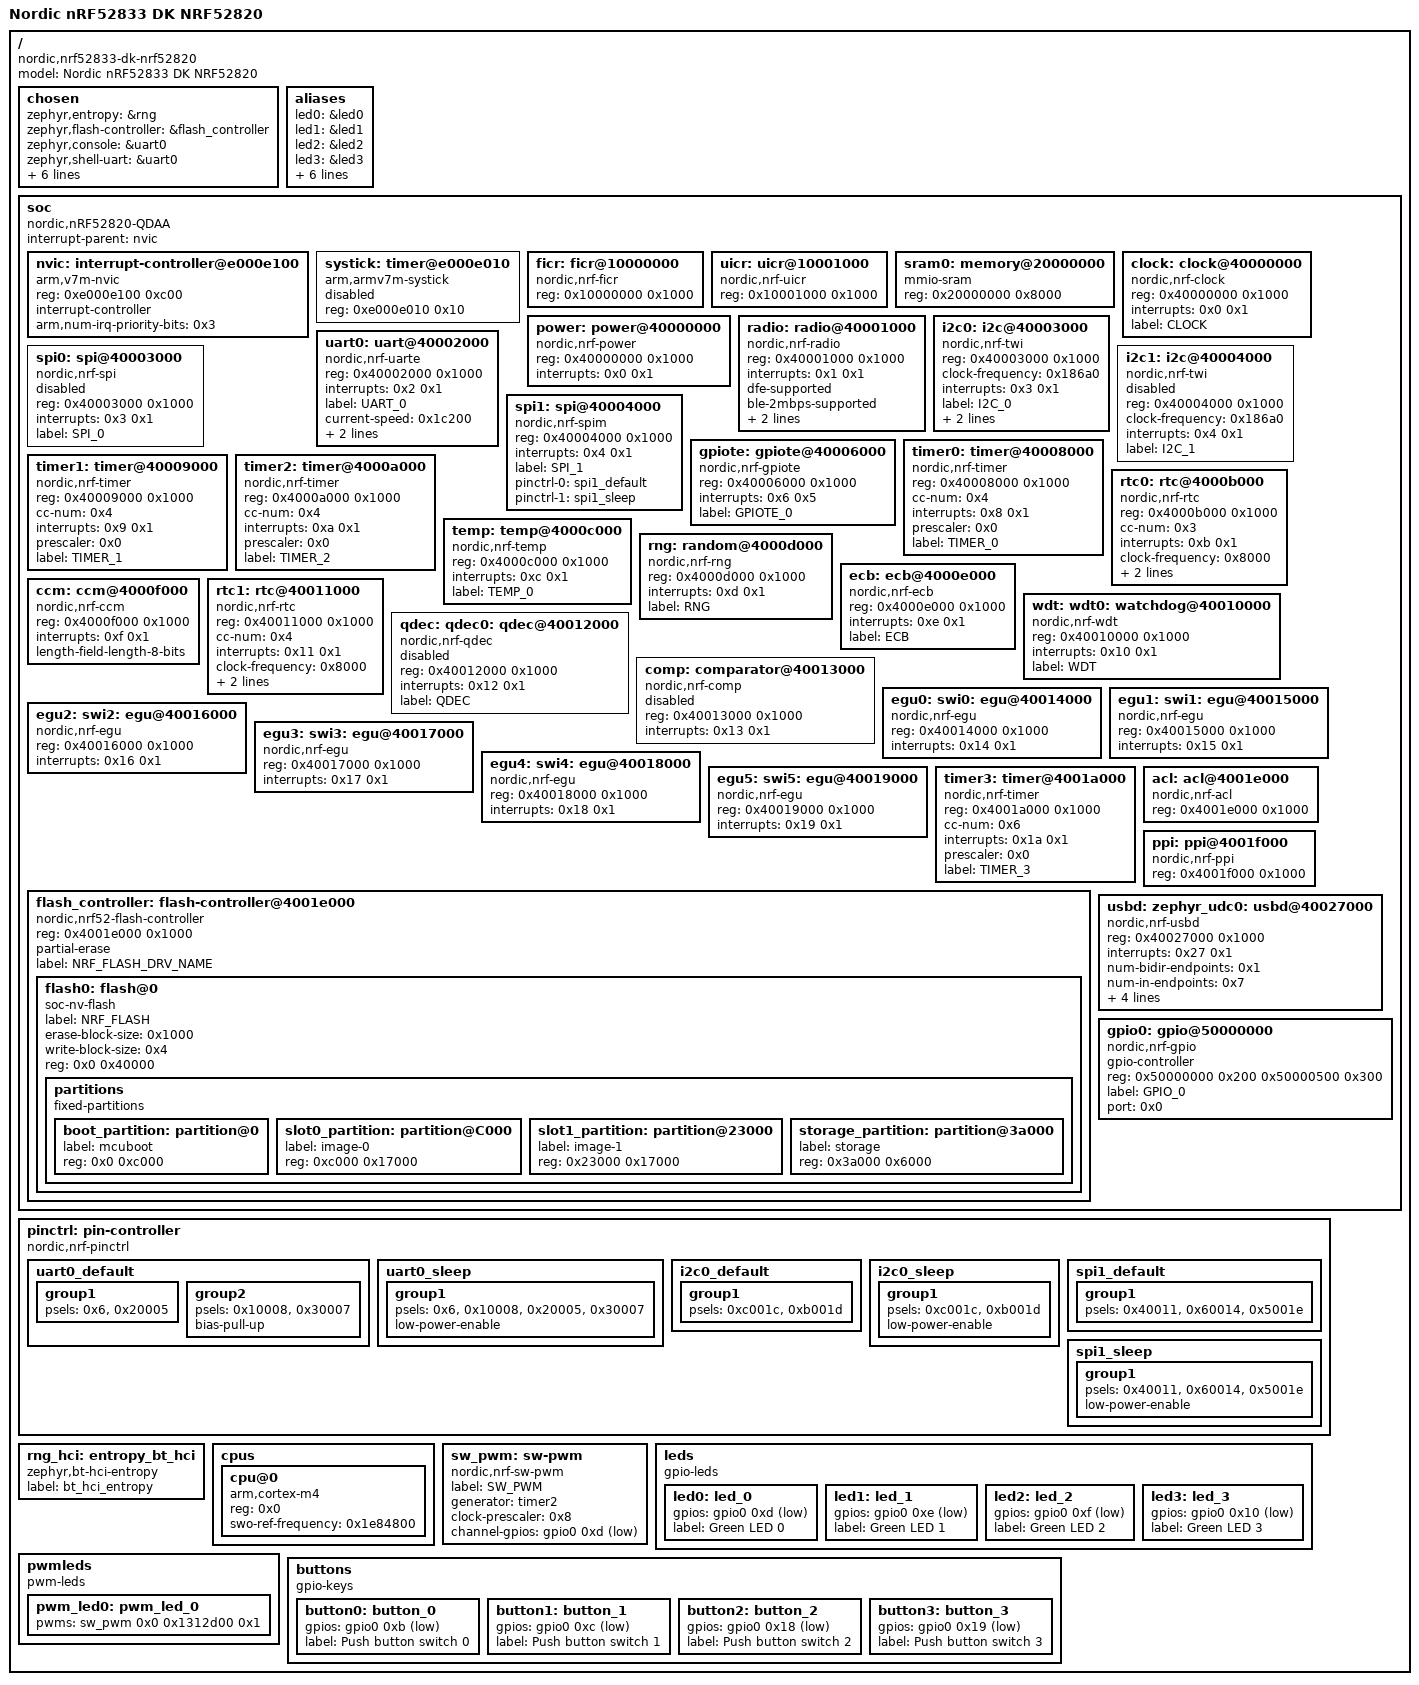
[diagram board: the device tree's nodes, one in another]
/dts-v1/;

/ {
	#address-cells = < 0x1 >;
	#size-cells = < 0x1 >;
	model = "Nordic nRF52833 DK NRF52820";
	compatible = "nordic,nrf52833-dk-nrf52820";
	chosen {
		zephyr,entropy = &rng;
		zephyr,flash-controller = &flash_controller;
		zephyr,console = &uart0;
		zephyr,shell-uart = &uart0;
		zephyr,uart-mcumgr = &uart0;
		zephyr,bt-mon-uart = &uart0;
		zephyr,bt-c2h-uart = &uart0;
		zephyr,sram = &sram0;
		zephyr,flash = &flash0;
		zephyr,code-partition = &slot0_partition;
	};
	aliases {
		led0 = &led0;
		led1 = &led1;
		led2 = &led2;
		led3 = &led3;
		pwm-led0 = &pwm_led0;
		sw0 = &button0;
		sw1 = &button1;
		sw2 = &button2;
		sw3 = &button3;
		bootloader-led0 = &led0;
	};
	soc {
		#address-cells = < 0x1 >;
		#size-cells = < 0x1 >;
		compatible = "nordic,nRF52820-QDAA", "nordic,nRF52820", "nordic,nRF52", "simple-bus";
		interrupt-parent = < &nvic >;
		ranges;
		nvic: interrupt-controller@e000e100 {
			#address-cells = < 0x1 >;
			compatible = "arm,v7m-nvic";
			reg = < 0xe000e100 0xc00 >;
			interrupt-controller;
			#interrupt-cells = < 0x2 >;
			arm,num-irq-priority-bits = < 0x3 >;
			phandle = < 0x1 >;
		};
		systick: timer@e000e010 {
			compatible = "arm,armv7m-systick";
			reg = < 0xe000e010 0x10 >;
			status = "disabled";
		};
		ficr: ficr@10000000 {
			compatible = "nordic,nrf-ficr";
			reg = < 0x10000000 0x1000 >;
			status = "okay";
		};
		uicr: uicr@10001000 {
			compatible = "nordic,nrf-uicr";
			reg = < 0x10001000 0x1000 >;
			status = "okay";
		};
		sram0: memory@20000000 {
			compatible = "mmio-sram";
			reg = < 0x20000000 0x8000 >;
		};
		clock: clock@40000000 {
			compatible = "nordic,nrf-clock";
			reg = < 0x40000000 0x1000 >;
			interrupts = < 0x0 0x1 >;
			status = "okay";
			label = "CLOCK";
		};
		power: power@40000000 {
			compatible = "nordic,nrf-power";
			reg = < 0x40000000 0x1000 >;
			interrupts = < 0x0 0x1 >;
			status = "okay";
		};
		radio: radio@40001000 {
			compatible = "nordic,nrf-radio";
			reg = < 0x40001000 0x1000 >;
			interrupts = < 0x1 0x1 >;
			status = "okay";
			dfe-supported;
			ble-2mbps-supported;
			ble-coded-phy-supported;
			tx-high-power-supported;
		};
		uart0: uart@40002000 {
			compatible = "nordic,nrf-uarte";
			reg = < 0x40002000 0x1000 >;
			interrupts = < 0x2 0x1 >;
			status = "okay";
			label = "UART_0";
			current-speed = < 0x1c200 >;
			pinctrl-0 = < &uart0_default >;
			pinctrl-1 = < &uart0_sleep >;
			pinctrl-names = "default", "sleep";
		};
		i2c0: i2c@40003000 {
			compatible = "nordic,nrf-twi";
			#address-cells = < 0x1 >;
			#size-cells = < 0x0 >;
			reg = < 0x40003000 0x1000 >;
			clock-frequency = < 0x186a0 >;
			interrupts = < 0x3 0x1 >;
			status = "okay";
			label = "I2C_0";
			pinctrl-0 = < &i2c0_default >;
			pinctrl-1 = < &i2c0_sleep >;
			pinctrl-names = "default", "sleep";
		};
		spi0: spi@40003000 {
			compatible = "nordic,nrf-spi";
			#address-cells = < 0x1 >;
			#size-cells = < 0x0 >;
			reg = < 0x40003000 0x1000 >;
			interrupts = < 0x3 0x1 >;
			status = "disabled";
			label = "SPI_0";
		};
		i2c1: i2c@40004000 {
			compatible = "nordic,nrf-twi";
			#address-cells = < 0x1 >;
			#size-cells = < 0x0 >;
			reg = < 0x40004000 0x1000 >;
			clock-frequency = < 0x186a0 >;
			interrupts = < 0x4 0x1 >;
			status = "disabled";
			label = "I2C_1";
		};
		spi1: spi@40004000 {
			compatible = "nordic,nrf-spim";
			#address-cells = < 0x1 >;
			#size-cells = < 0x0 >;
			reg = < 0x40004000 0x1000 >;
			interrupts = < 0x4 0x1 >;
			status = "okay";
			label = "SPI_1";
			pinctrl-0 = < &spi1_default >;
			pinctrl-1 = < &spi1_sleep >;
			pinctrl-names = "default", "sleep";
		};
		gpiote: gpiote@40006000 {
			compatible = "nordic,nrf-gpiote";
			reg = < 0x40006000 0x1000 >;
			interrupts = < 0x6 0x5 >;
			status = "okay";
			label = "GPIOTE_0";
		};
		timer0: timer@40008000 {
			compatible = "nordic,nrf-timer";
			status = "okay";
			reg = < 0x40008000 0x1000 >;
			cc-num = < 0x4 >;
			interrupts = < 0x8 0x1 >;
			prescaler = < 0x0 >;
			label = "TIMER_0";
		};
		timer1: timer@40009000 {
			compatible = "nordic,nrf-timer";
			status = "okay";
			reg = < 0x40009000 0x1000 >;
			cc-num = < 0x4 >;
			interrupts = < 0x9 0x1 >;
			prescaler = < 0x0 >;
			label = "TIMER_1";
		};
		timer2: timer@4000a000 {
			compatible = "nordic,nrf-timer";
			status = "okay";
			reg = < 0x4000a000 0x1000 >;
			cc-num = < 0x4 >;
			interrupts = < 0xa 0x1 >;
			prescaler = < 0x0 >;
			label = "TIMER_2";
			phandle = < 0x8 >;
		};
		rtc0: rtc@4000b000 {
			compatible = "nordic,nrf-rtc";
			reg = < 0x4000b000 0x1000 >;
			cc-num = < 0x3 >;
			interrupts = < 0xb 0x1 >;
			status = "okay";
			clock-frequency = < 0x8000 >;
			prescaler = < 0x1 >;
			label = "RTC_0";
		};
		temp: temp@4000c000 {
			compatible = "nordic,nrf-temp";
			reg = < 0x4000c000 0x1000 >;
			interrupts = < 0xc 0x1 >;
			status = "okay";
			label = "TEMP_0";
		};
		rng: random@4000d000 {
			compatible = "nordic,nrf-rng";
			reg = < 0x4000d000 0x1000 >;
			interrupts = < 0xd 0x1 >;
			status = "okay";
			label = "RNG";
		};
		ecb: ecb@4000e000 {
			compatible = "nordic,nrf-ecb";
			reg = < 0x4000e000 0x1000 >;
			interrupts = < 0xe 0x1 >;
			status = "okay";
			label = "ECB";
		};
		ccm: ccm@4000f000 {
			compatible = "nordic,nrf-ccm";
			reg = < 0x4000f000 0x1000 >;
			interrupts = < 0xf 0x1 >;
			length-field-length-8-bits;
			status = "okay";
		};
		wdt: wdt0: watchdog@40010000 {
			compatible = "nordic,nrf-wdt";
			reg = < 0x40010000 0x1000 >;
			interrupts = < 0x10 0x1 >;
			status = "okay";
			label = "WDT";
		};
		rtc1: rtc@40011000 {
			compatible = "nordic,nrf-rtc";
			reg = < 0x40011000 0x1000 >;
			cc-num = < 0x4 >;
			interrupts = < 0x11 0x1 >;
			status = "okay";
			clock-frequency = < 0x8000 >;
			prescaler = < 0x1 >;
			label = "RTC_1";
		};
		qdec: qdec0: qdec@40012000 {
			compatible = "nordic,nrf-qdec";
			reg = < 0x40012000 0x1000 >;
			interrupts = < 0x12 0x1 >;
			status = "disabled";
			label = "QDEC";
		};
		comp: comparator@40013000 {
			compatible = "nordic,nrf-comp";
			reg = < 0x40013000 0x1000 >;
			interrupts = < 0x13 0x1 >;
			status = "disabled";
			#io-channel-cells = < 0x1 >;
		};
		egu0: swi0: egu@40014000 {
			compatible = "nordic,nrf-egu", "nordic,nrf-swi";
			reg = < 0x40014000 0x1000 >;
			interrupts = < 0x14 0x1 >;
			status = "okay";
		};
		egu1: swi1: egu@40015000 {
			compatible = "nordic,nrf-egu", "nordic,nrf-swi";
			reg = < 0x40015000 0x1000 >;
			interrupts = < 0x15 0x1 >;
			status = "okay";
		};
		egu2: swi2: egu@40016000 {
			compatible = "nordic,nrf-egu", "nordic,nrf-swi";
			reg = < 0x40016000 0x1000 >;
			interrupts = < 0x16 0x1 >;
			status = "okay";
		};
		egu3: swi3: egu@40017000 {
			compatible = "nordic,nrf-egu", "nordic,nrf-swi";
			reg = < 0x40017000 0x1000 >;
			interrupts = < 0x17 0x1 >;
			status = "okay";
		};
		egu4: swi4: egu@40018000 {
			compatible = "nordic,nrf-egu", "nordic,nrf-swi";
			reg = < 0x40018000 0x1000 >;
			interrupts = < 0x18 0x1 >;
			status = "okay";
		};
		egu5: swi5: egu@40019000 {
			compatible = "nordic,nrf-egu", "nordic,nrf-swi";
			reg = < 0x40019000 0x1000 >;
			interrupts = < 0x19 0x1 >;
			status = "okay";
		};
		timer3: timer@4001a000 {
			compatible = "nordic,nrf-timer";
			status = "okay";
			reg = < 0x4001a000 0x1000 >;
			cc-num = < 0x6 >;
			interrupts = < 0x1a 0x1 >;
			prescaler = < 0x0 >;
			label = "TIMER_3";
		};
		acl: acl@4001e000 {
			compatible = "nordic,nrf-acl";
			reg = < 0x4001e000 0x1000 >;
			status = "okay";
		};
		flash_controller: flash-controller@4001e000 {
			compatible = "nordic,nrf52-flash-controller";
			reg = < 0x4001e000 0x1000 >;
			partial-erase;
			#address-cells = < 0x1 >;
			#size-cells = < 0x1 >;
			label = "NRF_FLASH_DRV_NAME";
			flash0: flash@0 {
				compatible = "soc-nv-flash";
				label = "NRF_FLASH";
				erase-block-size = < 0x1000 >;
				write-block-size = < 0x4 >;
				reg = < 0x0 0x40000 >;
				partitions {
					compatible = "fixed-partitions";
					#address-cells = < 0x1 >;
					#size-cells = < 0x1 >;
					boot_partition: partition@0 {
						label = "mcuboot";
						reg = < 0x0 0xc000 >;
					};
					slot0_partition: partition@C000 {
						label = "image-0";
						reg = < 0xc000 0x17000 >;
					};
					slot1_partition: partition@23000 {
						label = "image-1";
						reg = < 0x23000 0x17000 >;
					};
					storage_partition: partition@3a000 {
						label = "storage";
						reg = < 0x3a000 0x6000 >;
					};
				};
			};
		};
		ppi: ppi@4001f000 {
			compatible = "nordic,nrf-ppi";
			reg = < 0x4001f000 0x1000 >;
			status = "okay";
		};
		usbd: zephyr_udc0: usbd@40027000 {
			compatible = "nordic,nrf-usbd";
			reg = < 0x40027000 0x1000 >;
			interrupts = < 0x27 0x1 >;
			num-bidir-endpoints = < 0x1 >;
			num-in-endpoints = < 0x7 >;
			num-out-endpoints = < 0x7 >;
			num-isoin-endpoints = < 0x1 >;
			num-isoout-endpoints = < 0x1 >;
			status = "okay";
			label = "USBD";
		};
		gpio0: gpio@50000000 {
			compatible = "nordic,nrf-gpio";
			gpio-controller;
			reg = < 0x50000000 0x200 0x50000500 0x300 >;
			#gpio-cells = < 0x2 >;
			label = "GPIO_0";
			status = "okay";
			port = < 0x0 >;
			phandle = < 0x9 >;
		};
	};
	pinctrl: pin-controller {
		compatible = "nordic,nrf-pinctrl";
		uart0_default: uart0_default {
			phandle = < 0x2 >;
			group1 {
				psels = < 0x6 >, < 0x20005 >;
			};
			group2 {
				psels = < 0x10008 >, < 0x30007 >;
				bias-pull-up;
			};
		};
		uart0_sleep: uart0_sleep {
			phandle = < 0x3 >;
			group1 {
				psels = < 0x6 >, < 0x10008 >, < 0x20005 >, < 0x30007 >;
				low-power-enable;
			};
		};
		i2c0_default: i2c0_default {
			phandle = < 0x4 >;
			group1 {
				psels = < 0xc001c >, < 0xb001d >;
			};
		};
		i2c0_sleep: i2c0_sleep {
			phandle = < 0x5 >;
			group1 {
				psels = < 0xc001c >, < 0xb001d >;
				low-power-enable;
			};
		};
		spi1_default: spi1_default {
			phandle = < 0x6 >;
			group1 {
				psels = < 0x40011 >, < 0x60014 >, < 0x5001e >;
			};
		};
		spi1_sleep: spi1_sleep {
			phandle = < 0x7 >;
			group1 {
				psels = < 0x40011 >, < 0x60014 >, < 0x5001e >;
				low-power-enable;
			};
		};
	};
	rng_hci: entropy_bt_hci {
		compatible = "zephyr,bt-hci-entropy";
		label = "bt_hci_entropy";
		status = "okay";
	};
	cpus {
		#address-cells = < 0x1 >;
		#size-cells = < 0x0 >;
		cpu@0 {
			device_type = "cpu";
			compatible = "arm,cortex-m4";
			reg = < 0x0 >;
			swo-ref-frequency = < 0x1e84800 >;
		};
	};
	sw_pwm: sw-pwm {
		compatible = "nordic,nrf-sw-pwm";
		status = "okay";
		label = "SW_PWM";
		generator = < &timer2 >;
		clock-prescaler = < 0x8 >;
		#pwm-cells = < 0x3 >;
		channel-gpios = < &gpio0 0xd 0x1 >;
		phandle = < 0xa >;
	};
	leds {
		compatible = "gpio-leds";
		led0: led_0 {
			gpios = < &gpio0 0xd 0x1 >;
			label = "Green LED 0";
		};
		led1: led_1 {
			gpios = < &gpio0 0xe 0x1 >;
			label = "Green LED 1";
		};
		led2: led_2 {
			gpios = < &gpio0 0xf 0x1 >;
			label = "Green LED 2";
		};
		led3: led_3 {
			gpios = < &gpio0 0x10 0x1 >;
			label = "Green LED 3";
		};
	};
	pwmleds {
		compatible = "pwm-leds";
		pwm_led0: pwm_led_0 {
			pwms = < &sw_pwm 0x0 0x1312d00 0x1 >;
		};
	};
	buttons {
		compatible = "gpio-keys";
		button0: button_0 {
			gpios = < &gpio0 0xb 0x11 >;
			label = "Push button switch 0";
		};
		button1: button_1 {
			gpios = < &gpio0 0xc 0x11 >;
			label = "Push button switch 1";
		};
		button2: button_2 {
			gpios = < &gpio0 0x18 0x11 >;
			label = "Push button switch 2";
		};
		button3: button_3 {
			gpios = < &gpio0 0x19 0x11 >;
			label = "Push button switch 3";
		};
	};
};
